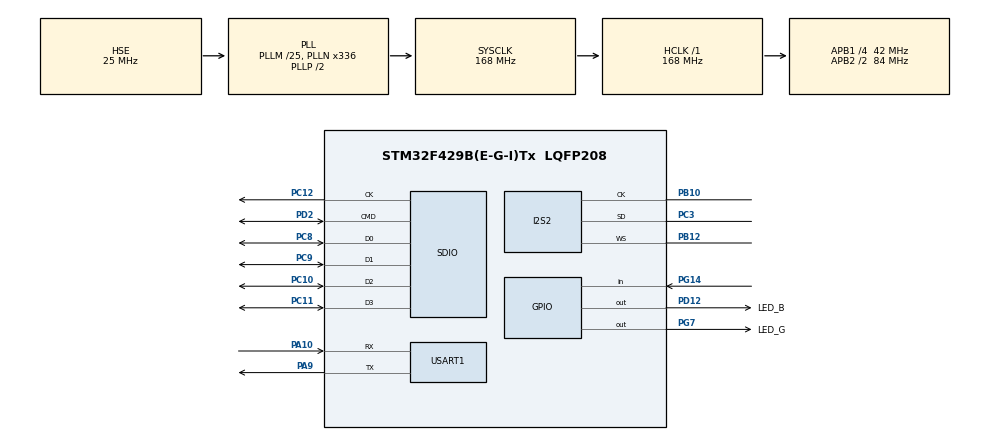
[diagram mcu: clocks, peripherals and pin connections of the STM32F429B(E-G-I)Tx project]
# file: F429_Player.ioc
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Dma.Request0=SDIO
Dma.Request1=USART1_RX
Dma.Request2=USART1_TX
Dma.Request3=SPI2_TX
Dma.SDIO.0.Direction=DMA_PERIPH_TO_MEMORY
Dma.SDIO.0.FIFOMode=DMA_FIFOMODE_ENABLE
Dma.SDIO.0.FIFOThreshold=DMA_FIFO_THRESHOLD_FULL
Dma.SDIO.0.Instance=DMA2_Stream3
Dma.SDIO.0.MemBurst=DMA_MBURST_INC4
Dma.SDIO.0.MemDataAlignment=DMA_MDATAALIGN_WORD
Dma.SDIO.0.MemInc=DMA_MINC_ENABLE
Dma.SDIO.0.Mode=DMA_PFCTRL
Dma.SDIO.0.PeriphBurst=DMA_PBURST_INC4
Dma.SDIO.0.PeriphDataAlignment=DMA_PDATAALIGN_WORD
Dma.SDIO.0.PeriphInc=DMA_PINC_DISABLE
Dma.SDIO.0.Priority=DMA_PRIORITY_LOW
Dma.SPI2_TX.3.Direction=DMA_MEMORY_TO_PERIPH
Dma.SPI2_TX.3.FIFOMode=DMA_FIFOMODE_DISABLE
Dma.SPI2_TX.3.Instance=DMA1_Stream4
Dma.SPI2_TX.3.MemDataAlignment=DMA_MDATAALIGN_HALFWORD
Dma.SPI2_TX.3.MemInc=DMA_MINC_ENABLE
Dma.SPI2_TX.3.Mode=DMA_CIRCULAR
Dma.SPI2_TX.3.PeriphDataAlignment=DMA_PDATAALIGN_HALFWORD
Dma.SPI2_TX.3.PeriphInc=DMA_PINC_DISABLE
Dma.SPI2_TX.3.Priority=DMA_PRIORITY_VERY_HIGH
Dma.USART1_RX.1.Direction=DMA_PERIPH_TO_MEMORY
Dma.USART1_RX.1.FIFOMode=DMA_FIFOMODE_DISABLE
Dma.USART1_RX.1.Instance=DMA2_Stream2
Dma.USART1_RX.1.MemDataAlignment=DMA_MDATAALIGN_BYTE
Dma.USART1_RX.1.MemInc=DMA_MINC_ENABLE
Dma.USART1_RX.1.Mode=DMA_NORMAL
Dma.USART1_RX.1.PeriphDataAlignment=DMA_PDATAALIGN_BYTE
Dma.USART1_RX.1.PeriphInc=DMA_PINC_DISABLE
Dma.USART1_RX.1.Priority=DMA_PRIORITY_LOW
Dma.USART1_TX.2.Direction=DMA_MEMORY_TO_PERIPH
Dma.USART1_TX.2.FIFOMode=DMA_FIFOMODE_DISABLE
Dma.USART1_TX.2.Instance=DMA2_Stream7
Dma.USART1_TX.2.MemDataAlignment=DMA_MDATAALIGN_BYTE
Dma.USART1_TX.2.MemInc=DMA_MINC_ENABLE
Dma.USART1_TX.2.Mode=DMA_NORMAL
Dma.USART1_TX.2.PeriphDataAlignment=DMA_PDATAALIGN_BYTE
Dma.USART1_TX.2.PeriphInc=DMA_PINC_DISABLE
Dma.USART1_TX.2.Priority=DMA_PRIORITY_LOW
FATFS.BSP.number=1
FATFS._CODE_PAGE=936
FATFS._FS_LOCK=8
FATFS._LFN_UNICODE=1
FATFS._USE_LFN=3
FATFS0.BSP.STBoard=false
FATFS0.BSP.api=Unknown
FATFS0.BSP.instance=PG14
FATFS0.BSP.ip=GPIO
FATFS0.BSP.mode=Input
FATFS0.BSP.name=Detect_SDIO
FATFS0.BSP.solution=PG14
FREERTOS.Tasks01=defaultTask,24,512,StartDefaultTask,Default,NULL,Dynamic,NULL,NULL
FREERTOS.configCHECK_FOR_STACK_OVERFLOW=2
FREERTOS.configMINIMAL_STACK_SIZE=512
FREERTOS.configTOTAL_HEAP_SIZE=65536
I2S2.AudioFreq=I2S_AUDIOFREQ_44K
I2S2.DataFormat=I2S_DATAFORMAT_16B
I2S2.ErrorAudioFreq=0.24 %
I2S2.FullDuplexMode=I2S_FULLDUPLEXMODE_DISABLE
I2S2.Instance=SPI$Index
I2S2.RealAudioFreq=44.108 KHz
I2S2.VirtualMode=I2S_MODE_MASTER
Mcu.Family=STM32F4
Mcu.Name=STM32F429B(E-G-I)Tx
Mcu.Package=LQFP208
NVIC.DMA1_Stream4_IRQn=true\:5\:0\:false\:false\:true\:true\:false\:true\:true
NVIC.DMA2_Stream2_IRQn=true\:5\:0\:false\:false\:true\:true\:false\:true\:true
NVIC.DMA2_Stream3_IRQn=true\:5\:0\:false\:false\:true\:true\:false\:true\:true
NVIC.DMA2_Stream7_IRQn=true\:5\:0\:false\:false\:true\:true\:false\:true\:true
NVIC.PriorityGroup=NVIC_PRIORITYGROUP_4
NVIC.SDIO_IRQn=true\:6\:0\:true\:false\:true\:true\:true\:true\:true
NVIC.SPI2_IRQn=true\:5\:0\:false\:false\:true\:true\:true\:true\:true
NVIC.TIM1_UP_TIM10_IRQn=true\:15\:0\:false\:false\:true\:false\:false\:true\:true
NVIC.TimeBase=TIM1_UP_TIM10_IRQn
NVIC.TimeBaseIP=TIM1
NVIC.USART1_IRQn=true\:5\:0\:false\:false\:true\:true\:true\:true\:true
PA10.Mode=Asynchronous
PA10.Signal=USART1_RX
PA13.Mode=Serial_Wire
PA13.Signal=SYS_JTMS-SWDIO
PA14.Mode=Serial_Wire
PA14.Signal=SYS_JTCK-SWCLK
PA9.Mode=Asynchronous
PA9.Signal=USART1_TX
PB10.GPIO_Speed=GPIO_SPEED_FREQ_HIGH
PB10.Mode=Half_Duplex_Master
PB10.Signal=I2S2_CK
PB12.GPIO_Speed=GPIO_SPEED_FREQ_HIGH
PB12.Mode=Half_Duplex_Master
PB12.Signal=I2S2_WS
PC10.GPIO_PuPd=GPIO_PULLUP
PC10.Mode=SD_4_bits_Wide_bus
PC10.Signal=SDIO_D2
PC11.GPIO_PuPd=GPIO_PULLUP
PC11.Mode=SD_4_bits_Wide_bus
PC11.Signal=SDIO_D3
PC12.GPIO_PuPd=GPIO_NOPULL
PC12.Mode=SD_4_bits_Wide_bus
PC12.Signal=SDIO_CK
PC3.GPIO_Speed=GPIO_SPEED_FREQ_HIGH
PC3.Mode=Half_Duplex_Master
PC3.Signal=I2S2_SD
PC8.GPIO_PuPd=GPIO_PULLUP
PC8.Mode=SD_4_bits_Wide_bus
PC8.Signal=SDIO_D0
PC9.GPIO_PuPd=GPIO_PULLUP
PC9.Mode=SD_4_bits_Wide_bus
PC9.Signal=SDIO_D1
PD12.GPIO_Label=LED_B
PD12.Signal=GPIO_Output
PD2.GPIO_PuPd=GPIO_PULLUP
PD2.Mode=SD_4_bits_Wide_bus
PD2.Signal=SDIO_CMD
PG14.GPIO_PuPd=GPIO_PULLUP
PG14.Signal=GPIO_Input
PG7.GPIO_Label=LED_G
PG7.Signal=GPIO_Output
PH0/OSC_IN.Mode=HSE-External-Oscillator
PH0/OSC_IN.Signal=RCC_OSC_IN
PH1/OSC_OUT.Mode=HSE-External-Oscillator
PH1/OSC_OUT.Signal=RCC_OSC_OUT
ProjectManager.HeapSize=0x200
ProjectManager.StackSize=0x400
ProjectManager.TargetToolchain=CMake
RCC.48MHZClocksFreq_Value=48000000
RCC.AHBFreq_Value=168000000
RCC.APB1CLKDivider=RCC_HCLK_DIV4
RCC.APB1Freq_Value=42000000
RCC.APB1TimFreq_Value=84000000
RCC.APB2CLKDivider=RCC_HCLK_DIV2
RCC.APB2Freq_Value=84000000
RCC.APB2TimFreq_Value=168000000
RCC.CortexFreq_Value=168000000
RCC.HCLKFreq_Value=168000000
RCC.HSE_VALUE=25000000
RCC.HSI_VALUE=16000000
RCC.LSE_VALUE=32768
RCC.PLLI2SN=271
RCC.PLLI2SQ=15
RCC.PLLI2SR=6
RCC.PLLM=25
RCC.PLLN=336
RCC.PLLQ=7
RCC.PLLSAIN=258
RCC.PLLSAIQ=3
RCC.PLLSourceVirtual=RCC_PLLSOURCE_HSE
RCC.SYSCLKFreq_VALUE=168000000
RCC.SYSCLKSource=RCC_SYSCLKSOURCE_PLLCLK
RCC.VCOOutputFreq_Value=336000000
SDIO.HardwareFlowControl=SDIO_HARDWARE_FLOW_CONTROL_DISABLE
USART1.VirtualMode=VM_ASYNC
VP_FATFS_VS_SDIO.Mode=SDIO
VP_FREERTOS_VS_CMSIS_V2.Mode=CMSIS_V2
VP_SYS_VS_tim1.Mode=TIM1
board=custom

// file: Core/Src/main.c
/* USER CODE BEGIN Header */
/**
  ******************************************************************************
  * @file           : main.c
  * @brief          : Main program body
  ******************************************************************************
  * @attention
  *
  * Copyright (c) 2026 STMicroelectronics.
  * All rights reserved.
  *
  * This software is licensed under terms that can be found in the LICENSE file
  * in the root directory of this software component.
  * If no LICENSE file comes with this software, it is provided AS-IS.
  *
  ******************************************************************************
  */
/* USER CODE END Header */
#include "main.h"
#include "cmsis_os.h"
#include "dma.h"
#include "fatfs.h"
#include "i2s.h"
#include "sdio.h"
#include "usart.h"
#include "gpio.h"

void SystemClock_Config(void);
void MX_FREERTOS_Init(void);

int main(void)
{

  /* MCU Configuration--------------------------------------------------------*/

  /* Reset of all peripherals, Initializes the Flash interface and the Systick. */
  HAL_Init();

  /* Configure the system clock */
  SystemClock_Config();

  /* Initialize all configured peripherals */
  MX_GPIO_Init();
  MX_DMA_Init();
  MX_SDIO_SD_Init();
  MX_USART1_UART_Init();
  MX_FATFS_Init();
  MX_I2S2_Init();

  /* Init scheduler */
  osKernelInitialize();  /* Call init function for freertos objects (in cmsis_os2.c) */
  MX_FREERTOS_Init();

  /* Start scheduler */
  osKernelStart();

  /* We should never get here as control is now taken by the scheduler */

  /* Infinite loop */
  while (1)
  {

  }
}

void SystemClock_Config(void)
{
  RCC_OscInitTypeDef RCC_OscInitStruct = {0};
  RCC_ClkInitTypeDef RCC_ClkInitStruct = {0};

  /** Configure the main internal regulator output voltage
  */
  __HAL_RCC_PWR_CLK_ENABLE();
  __HAL_PWR_VOLTAGESCALING_CONFIG(PWR_REGULATOR_VOLTAGE_SCALE1);

  /** Initializes the RCC Oscillators according to the specified parameters
  * in the RCC_OscInitTypeDef structure.
  */
  RCC_OscInitStruct.OscillatorType = RCC_OSCILLATORTYPE_HSE;
  RCC_OscInitStruct.HSEState = RCC_HSE_ON;
  RCC_OscInitStruct.PLL.PLLState = RCC_PLL_ON;
  RCC_OscInitStruct.PLL.PLLSource = RCC_PLLSOURCE_HSE;
  RCC_OscInitStruct.PLL.PLLM = 25;
  RCC_OscInitStruct.PLL.PLLN = 336;
  RCC_OscInitStruct.PLL.PLLP = RCC_PLLP_DIV2;
  RCC_OscInitStruct.PLL.PLLQ = 7;
  if (HAL_RCC_OscConfig(&RCC_OscInitStruct) != HAL_OK)
  {
    Error_Handler();
  }

  /** Initializes the CPU, AHB and APB buses clocks
  */
  RCC_ClkInitStruct.ClockType = RCC_CLOCKTYPE_HCLK|RCC_CLOCKTYPE_SYSCLK
                              |RCC_CLOCKTYPE_PCLK1|RCC_CLOCKTYPE_PCLK2;
  RCC_ClkInitStruct.SYSCLKSource = RCC_SYSCLKSOURCE_PLLCLK;
  RCC_ClkInitStruct.AHBCLKDivider = RCC_SYSCLK_DIV1;
  RCC_ClkInitStruct.APB1CLKDivider = RCC_HCLK_DIV4;
  RCC_ClkInitStruct.APB2CLKDivider = RCC_HCLK_DIV2;

  if (HAL_RCC_ClockConfig(&RCC_ClkInitStruct, FLASH_LATENCY_5) != HAL_OK)
  {
    Error_Handler();
  }
}

void HAL_TIM_PeriodElapsedCallback(TIM_HandleTypeDef *htim)
{
  if (htim->Instance == TIM1)
  {
    HAL_IncTick();
  }
}

void Error_Handler(void)
{
  __disable_irq();
  while (1)
  {
  }
}

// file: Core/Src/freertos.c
/* USER CODE BEGIN Header */
/**
  ******************************************************************************
  * File Name          : freertos.c
  * Description        : Code for freertos applications
  ******************************************************************************
  * @attention
  *
  * Copyright (c) 2026 STMicroelectronics.
  * All rights reserved.
  *
  * This software is licensed under terms that can be found in the LICENSE file
  * in the root directory of this software component.
  * If no LICENSE file comes with this software, it is provided AS-IS.
  *
  ******************************************************************************
  */
/* USER CODE END Header */

#include "FreeRTOS.h"
#include "task.h"
#include "main.h"
#include "cmsis_os.h"

/* Definitions for defaultTask */
osThreadId_t defaultTaskHandle;
const osThreadAttr_t defaultTask_attributes = {
  .name = "defaultTask",
  .stack_size = 512 * 4,
  .priority = (osPriority_t) osPriorityNormal,
};

void StartDefaultTask(void *argument);

void MX_FREERTOS_Init(void); /* (MISRA C 2004 rule 8.1) */

/* Hook prototypes */
void vApplicationStackOverflowHook(xTaskHandle xTask, signed char *pcTaskName);

/* USER CODE BEGIN 4 */
void vApplicationStackOverflowHook(xTaskHandle xTask, signed char *pcTaskName)
{
  (void)xTask;
  printf("Stack overflow in task: %s\n", (char *)pcTaskName);
  taskDISABLE_INTERRUPTS();
  for(;;);
}
/* USER CODE END 4 */

void MX_FREERTOS_Init(void) {

  /* Create the thread(s) */
  /* creation of defaultTask */
  defaultTaskHandle = osThreadNew(StartDefaultTask, NULL, &defaultTask_attributes);

}

void StartDefaultTask(void *argument)
{
  /* USER CODE BEGIN StartDefaultTask */
  void app_main(void);
  app_main();
  vTaskDelete(NULL);
  /* Infinite loop */
  for(;;)
  {
    osDelay(1);
  }
  /* USER CODE END StartDefaultTask */
}
